# I94100_v1_3 register map
File version: 1.0
Registers are 32-bit, read-write, reset 0x0 unless marked. A register's access mark holds for its fields unless they carry their own. Offsets are from the block's base; [hi:lo] are bit positions; {n}, {i} and the like mark numbered series; 'fields as' and 'values as' point back to an identical list.

## GPIO — GPIO Register Map
Base 0x40004000
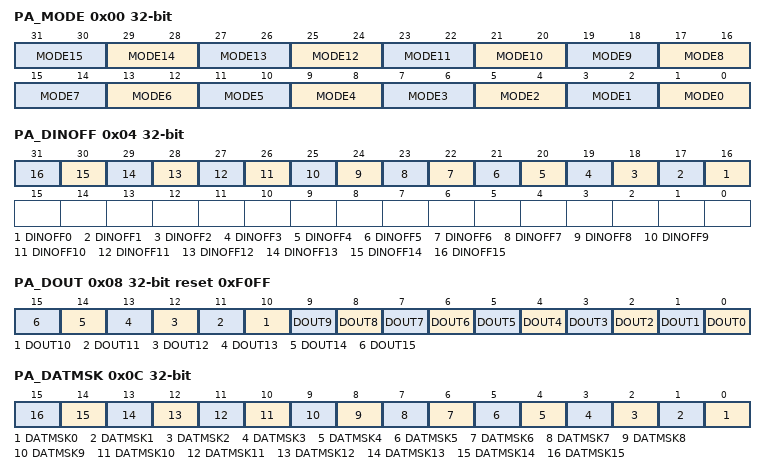
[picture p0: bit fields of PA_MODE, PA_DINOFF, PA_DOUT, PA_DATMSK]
0x00 PA_MODE reset not defined — PA I/O Mode Control
  [all] fields
    0=Px.n is in Input mode; 1=Px.n is in Push-pull Output mode; 2=Px.n is in Open-drain Output mode; 3=Px.n is in Quasi-bidirectional mode
  [2n+1:2n] MODE{n} (n=0..15) — Port A-D I/O Pin[n] Mode Control. Determine each I/O mode of Px.n pins.
0x04 PA_DINOFF — PA Digital Input Path Disable Control
  [all] fields
    0=Px.n digital input path Enabled; 1=Px.n digital input path Disabled (digital input tied to low)
  [n+16] DINOFF{n} (n=0..15) — Port A-D Pin[n] Digital Input Path Disable Control. Each of these bits is used to control if the digital input path of corresponding Px.n pin is disabled. If input is analog signal, users can disable Px.n digital input path to avoid input current leakage.
0x08 PA_DOUT reset 0xF0FF (reset mask 0xFFFFF0FF) — PA Data Output Value
  [all] fields
    0=Px.n will drive Low if the Px.n pin is configured as Push-pull output, Open-drain output or Quasi-bidirectional mode; 1=Px.n will drive High if the Px.n pin is configured as Push-pull output or Quasi-bidirectional mode
  [n] DOUT{n} (n=0..15) — Port A-D Pin[n] Output Value. Each of these bits controls the status of a Px.n pin when the Px.n is configured as Push-pull output, Open-drain output or Quasi-bidirectional mode.
0x0C PA_DATMSK — PA Data Output Write Mask
  [all] fields
    0=Corresponding DOUT (Px_DOUT[n]) bit can be updated; 1=Corresponding DOUT (Px_DOUT[n]) bit protected
  [n] DATMSK{n} (n=0..15) — Port A-D Pin[n] Data Output Write Mask. These bits are used to protect the corresponding DOUT (Px_DOUT[n]) bit. When the DATMSK (Px_DATMSK[n]) bit is set to 1, the corresponding DOUT (Px_DOUT[n]) bit is protected. If the write signal is masked, writing data to the protect bit is ignored.
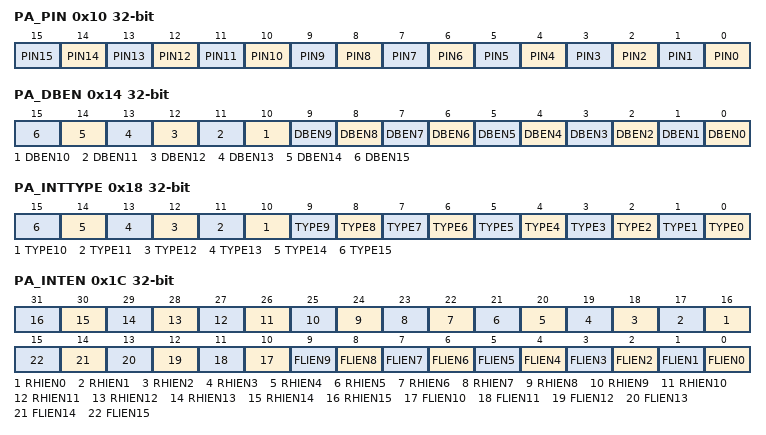
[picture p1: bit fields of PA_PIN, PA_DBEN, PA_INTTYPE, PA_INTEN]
0x10 PA_PIN ro (reset mask 0xFFFF0000) — PA Pin Value
  [n] PIN{n} (n=0..15) — Port A-D Pin[n] Pin Value. Each bit of the register reflects the actual status of the respective Px.n pin. If the bit is 1, it indicates the corresponding pin status is high; else the pin status is low. Note 1: The reset value of PB_PIN[15:8] is XXXX_00XXb in binary form. Note 2:
0x14 PA_DBEN — PA De-bounce Enable Control Register
  [all] fields
    0=Px.n de-bounce function Disabled; 1=Px.n de-bounce function Enabled
  [n] DBEN{n} (n=0..15) — Port A-D Pin[n] Input Signal De-bounce Enable Bit. The DBEN[n] bit is used to enable the de-bounce function for each corresponding bit. If the input signal pulse width cannot be sampled by continuous two de-bounce sample cycle, the input signal transition is seen as the signal bounce and will not trigger the interrupt. The de-bounce clock source is controlled by DBCLKSRC (GPIO_DBCTL [4]), one de-bounce sample cycle period is controlled by DBCLKSEL (GPIO_DBCTL [3:0]).
0x18 PA_INTTYPE — PA Interrupt Trigger Type Control
  [all] fields
    0=Edge trigger interrupt; 1=Level trigger interrupt
  [n] TYPE{n} (n=0..15) — Port A-D Pin[n] Edge or Level Detection Interrupt Trigger Type Control. TYPE (Px_INTTYPE[n]) bit is used to control the triggered interrupt is by level trigger or by edge trigger. If the interrupt is by edge trigger, the trigger source can be controlled by de-bounce. If the interrupt is by level trigger, the input source is sampled by one HCLK clock and generates the interrupt.
0x1C PA_INTEN — PA Interrupt Enable Control Register
  [n+16] RHIEN{n} (n=0..15) — Port A-D Pin[n] Rising Edge or High Level Interrupt Trigger Type Enable Bit. The RHIEN (Px_INTEN[n+16]) bit is used to enable the interrupt for each of the corresponding input Px.n pin. Set bit to 1 also enable the pin wake-up function. When setting the RHIEN (Px_INTEN[n+16]) bit to 1 : If the interrupt is level trigger (TYPE (Px_INTTYPE[n]) bit is set to 1), the input Px.n pin will generate the interrupt while this pin state is at high level. If the interrupt is edge trigger (TYPE (Px_INTTYPE[n]) bit is set to 0), the input Px.n pin will generate the interrupt while this pin state changed from low to high.
    0=Px.n level high or low to high interrupt Disabled; 1=Px.n level high or low to high interrupt Enabled
  [n] FLIEN{n} (n=0..15) — Port A-D Pin[n] Falling Edge or Low Level Interrupt Trigger Type Enable Bit. The FLIEN (Px_INTEN[n]) bit is used to enable the interrupt for each of the corresponding input Px.n pin. Set bit to 1 also enable the pin wake-up function. When setting the FLIEN (Px_INTEN[n]) bit to 1 : If the interrupt is level trigger (TYPE (Px_INTTYPE[n]) bit is set to 1), the input Px.n pin will generate the interrupt while this pin state is at low level. If the interrupt is edge trigger(TYPE (Px_INTTYPE[n]) bit is set to 0), the input Px.n pin will generate the interrupt while this pin state changed from high to low.
    0=Px.n level low or high to low interrupt Disabled; 1=Px.n level low or high to low interrupt Enabled
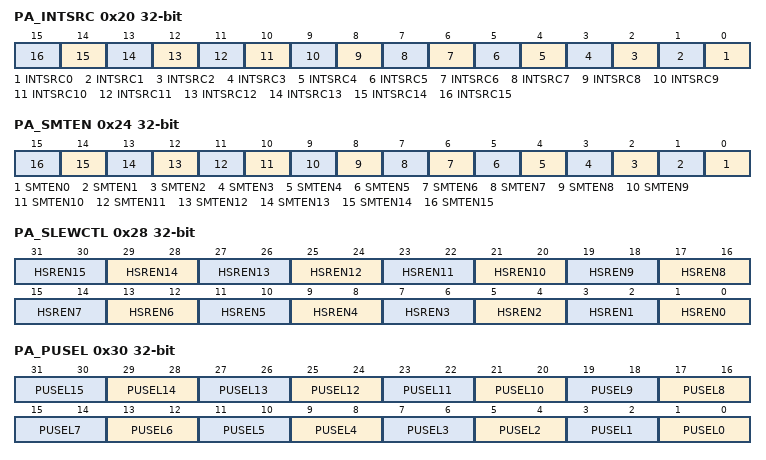
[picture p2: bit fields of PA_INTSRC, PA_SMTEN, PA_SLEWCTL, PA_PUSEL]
0x20 PA_INTSRC — PA Interrupt Source Flag
  [all] fields
    0=No action. No interrupt at Px.n; 1=Clear the corresponding pending interrupt. Px.n generates an interrupt
  [n] INTSRC{n} (n=0..15) — Port A-D Pin[n] Interrupt Source Flag. Write Operation :
0x24 PA_SMTEN — PA Input Schmitt Trigger Enable Register
  [all] fields
    0=Px.n input schmitt trigger function Disabled; 1=Px.n input schmitt trigger function Enabled
  [n] SMTEN{n} (n=0..15) — Port A-D Pin[n] Input Schmitt Trigger Enable Bit
0x28 PA_SLEWCTL — PA High Slew Rate Control Register
  [all] fields
    0=Px.n output with normal slew rate mode; 1=Px.n output with high slew rate mode; 2=Px.n output with fast slew rate mode; 3=Reserved. Do not use
  [2n+1:2n] HSREN{n} (n=0..15) — Port A-D Pin[n] High Slew Rate Control
0x30 PA_PUSEL — PA Pull-up and Pull-down Selection Register
  [all] fields
    0=Px.n pull-up and pull- down disable; 1=Px.n pull-up enable; 2=Px.n pull-down enable; 3=Px.n pull-up and pull-down disable
  [2n+1:2n] PUSEL{n} (n=0..15) — Port A-D Pin[n] Pull-up and Pull-down Enable Register. Determine each I/O Pull-up/pull-down of Px.n pins.
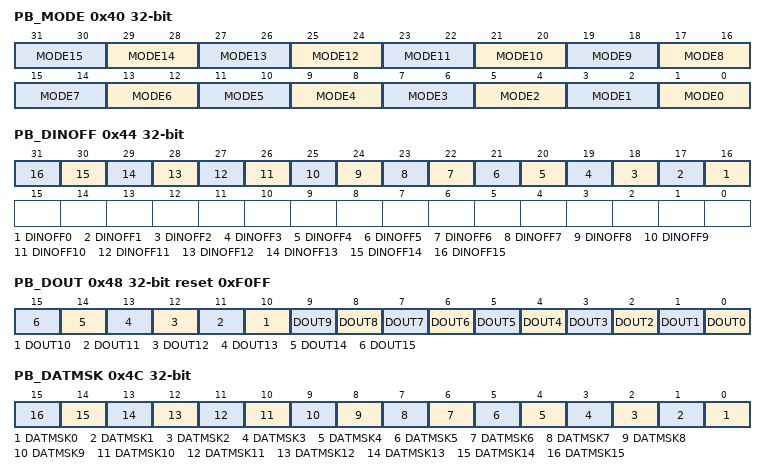
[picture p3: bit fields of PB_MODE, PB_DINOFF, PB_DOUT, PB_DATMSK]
0x40 PB_MODE reset not defined — PB I/O Mode Control
  fields as PA_MODE
0x44 PB_DINOFF — PB Digital Input Path Disable Control
  fields as PA_DINOFF
0x48 PB_DOUT reset 0xF0FF (reset mask 0xFFFFF0FF) — PB Data Output Value
  fields as PA_DOUT
0x4C PB_DATMSK — PB Data Output Write Mask
  fields as PA_DATMSK
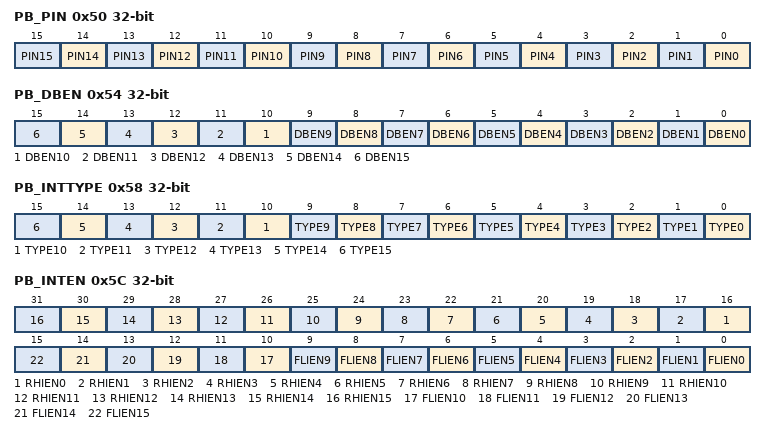
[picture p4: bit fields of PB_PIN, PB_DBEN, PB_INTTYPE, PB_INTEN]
0x50 PB_PIN ro (reset mask 0xFFFF0000) — PB Pin Value
  fields as PA_PIN
0x54 PB_DBEN — PB De-bounce Enable Control Register
  fields as PA_DBEN
0x58 PB_INTTYPE — PB Interrupt Trigger Type Control
  fields as PA_INTTYPE
0x5C PB_INTEN — PB Interrupt Enable Control Register
  fields as PA_INTEN
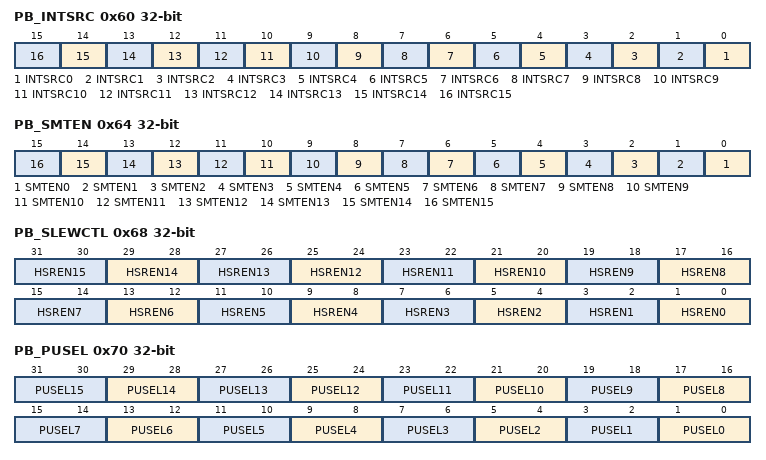
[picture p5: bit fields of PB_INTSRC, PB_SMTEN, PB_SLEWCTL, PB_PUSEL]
0x60 PB_INTSRC — PB Interrupt Source Flag
  fields as PA_INTSRC
0x64 PB_SMTEN — PB Input Schmitt Trigger Enable Register
  fields as PA_SMTEN
0x68 PB_SLEWCTL — PB High Slew Rate Control Register
  fields as PA_SLEWCTL
0x70 PB_PUSEL — PB Pull-up and Pull-down Selection Register
  fields as PA_PUSEL
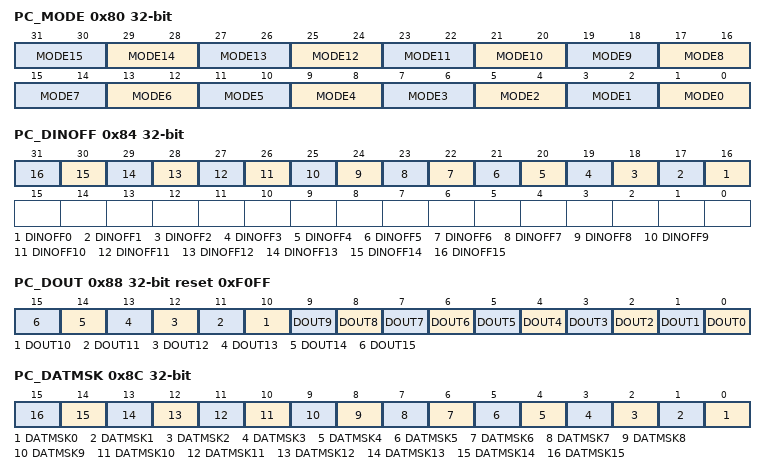
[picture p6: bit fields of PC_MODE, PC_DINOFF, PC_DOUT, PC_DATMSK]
0x80 PC_MODE reset not defined — PC I/O Mode Control
  fields as PA_MODE
0x84 PC_DINOFF — PC Digital Input Path Disable Control
  fields as PA_DINOFF
0x88 PC_DOUT reset 0xF0FF (reset mask 0xFFFFF0FF) — PC Data Output Value
  fields as PA_DOUT
0x8C PC_DATMSK — PC Data Output Write Mask
  fields as PA_DATMSK
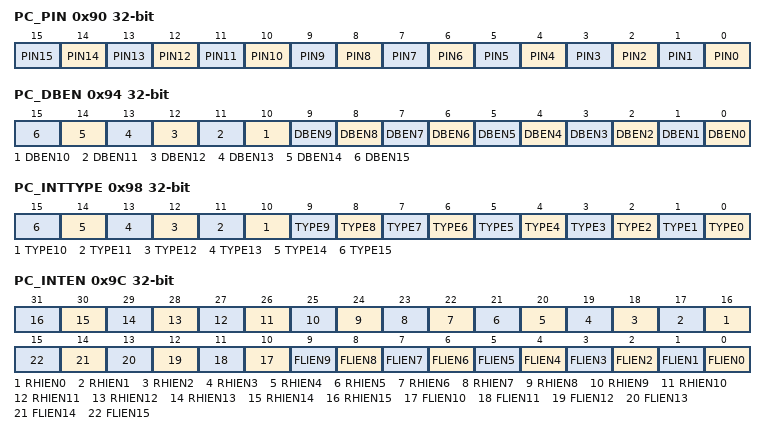
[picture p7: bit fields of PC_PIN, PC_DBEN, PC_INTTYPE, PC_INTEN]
0x90 PC_PIN ro (reset mask 0xFFFF0000) — PC Pin Value
  fields as PA_PIN
0x94 PC_DBEN — PC De-bounce Enable Control Register
  fields as PA_DBEN
0x98 PC_INTTYPE — PC Interrupt Trigger Type Control
  fields as PA_INTTYPE
0x9C PC_INTEN — PC Interrupt Enable Control Register
  fields as PA_INTEN
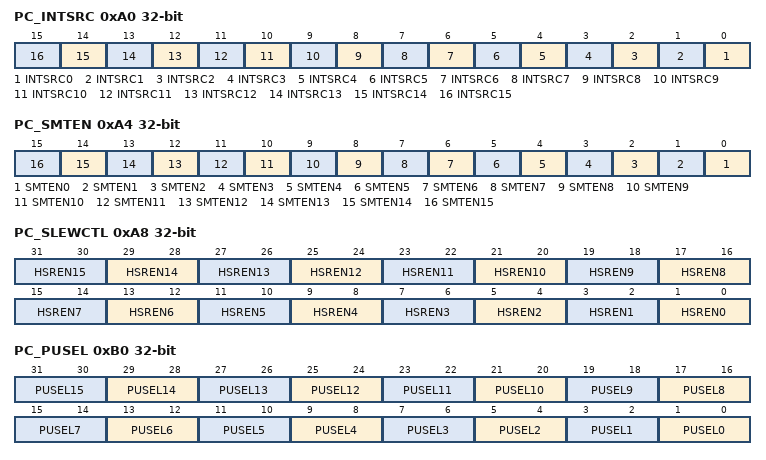
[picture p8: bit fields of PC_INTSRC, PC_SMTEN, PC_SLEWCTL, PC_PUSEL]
0xA0 PC_INTSRC — PC Interrupt Source Flag
  fields as PA_INTSRC
0xA4 PC_SMTEN — PC Input Schmitt Trigger Enable Register
  fields as PA_SMTEN
0xA8 PC_SLEWCTL — PC High Slew Rate Control Register
  fields as PA_SLEWCTL
0xB0 PC_PUSEL — PC Pull-up and Pull-down Selection Register
  fields as PA_PUSEL
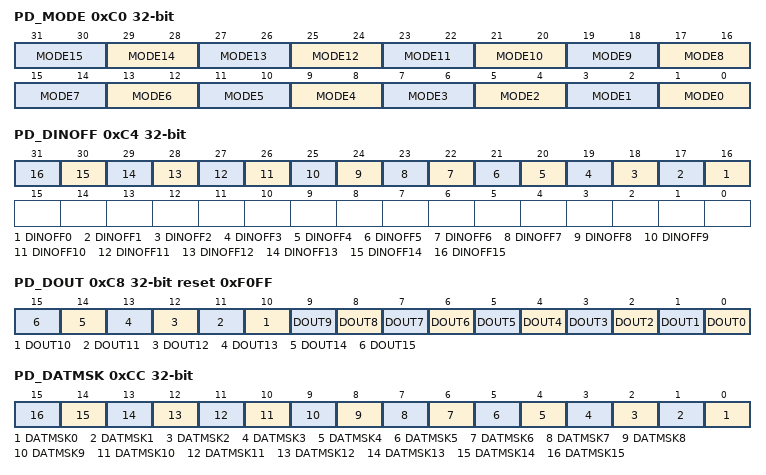
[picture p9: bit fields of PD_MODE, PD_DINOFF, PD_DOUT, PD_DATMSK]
0xC0 PD_MODE reset not defined — PD I/O Mode Control
  fields as PA_MODE
0xC4 PD_DINOFF — PD Digital Input Path Disable Control
  fields as PA_DINOFF
0xC8 PD_DOUT reset 0xF0FF (reset mask 0xFFFFF0FF) — PD Data Output Value
  fields as PA_DOUT
0xCC PD_DATMSK — PD Data Output Write Mask
  fields as PA_DATMSK
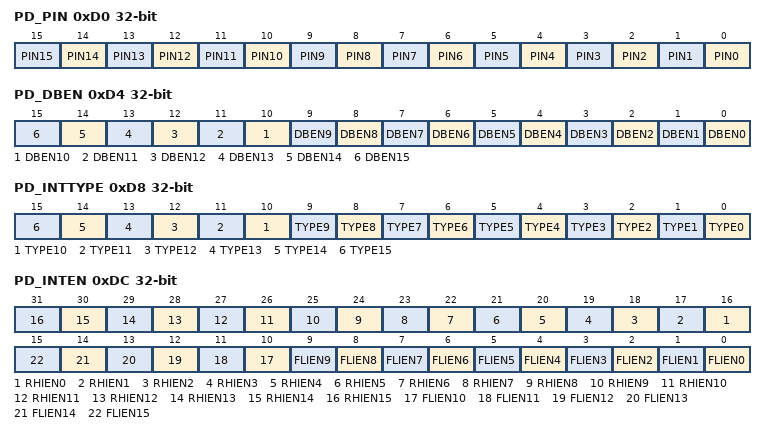
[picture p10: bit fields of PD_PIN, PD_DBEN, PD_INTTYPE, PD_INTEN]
0xD0 PD_PIN ro (reset mask 0xFFFF0000) — PD Pin Value
  fields as PA_PIN
0xD4 PD_DBEN — PD De-bounce Enable Control Register
  fields as PA_DBEN
0xD8 PD_INTTYPE — PD Interrupt Trigger Type Control
  fields as PA_INTTYPE
0xDC PD_INTEN — PD Interrupt Enable Control Register
  fields as PA_INTEN
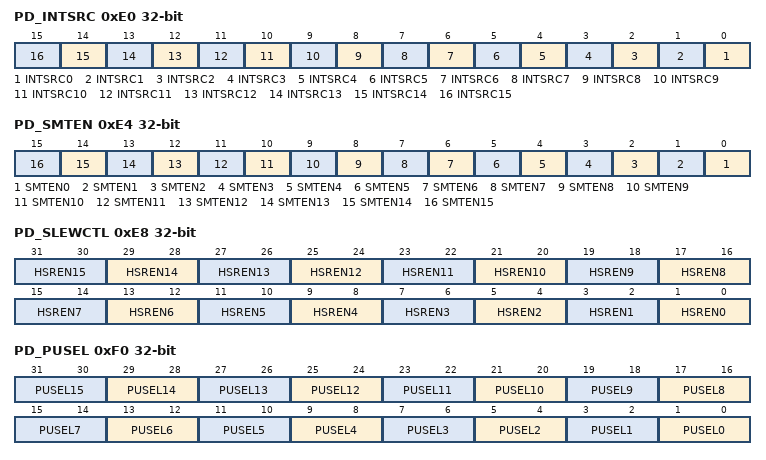
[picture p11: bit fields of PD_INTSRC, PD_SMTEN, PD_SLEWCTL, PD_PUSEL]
0xE0 PD_INTSRC — PD Interrupt Source Flag
  fields as PA_INTSRC
0xE4 PD_SMTEN — PD Input Schmitt Trigger Enable Register
  fields as PA_SMTEN
0xE8 PD_SLEWCTL — PD High Slew Rate Control Register
  fields as PA_SLEWCTL
0xF0 PD_PUSEL — PD Pull-up and Pull-down Selection Register
  fields as PA_PUSEL
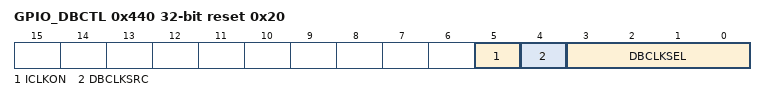
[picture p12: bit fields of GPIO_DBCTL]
0x440 GPIO_DBCTL reset 0x20 — Interrupt De-bounce Control Register
  [5] ICLKON — Interrupt Clock on Mode. Note: It is recommended to disable this bit to save system power if no special application concern.
    0=Edge detection circuit is active only if I/O pin corresponding RHIEN (Px_INTEN[n+16])/FLIEN (Px_INTEN[n]) bit is set to 1; 1=All I/O pins edge detection circuit is always active after reset
  [4] DBCLKSRC — De-bounce Counter Clock Source Selection
    0=De-bounce counter clock source is the HCLK; 1=De-bounce counter clock source is the 10 kHz internal low speed RC oscillator (LIRC)
  [3:0] DBCLKSEL — De-bounce Sampling Cycle Selection
    0=Sample interrupt input once per 1 clocks; 1=Sample interrupt input once per 2 clocks; 2=Sample interrupt input once per 4 clocks; 3=Sample interrupt input once per 8 clocks; 4=Sample interrupt input once per 16 clocks; 5=Sample interrupt input once per 32 clocks; 6=Sample interrupt input once per 64 clocks; 7=Sample interrupt input once per 128 clocks; 8=Sample interrupt input once per 256 clocks; 9=Sample interrupt input once per 2*256 clocks; 10=Sample interrupt input once per 4*256 clocks; 11=Sample interrupt input once per 8*256 clocks; 12=Sample interrupt input once per 16*256 clocks; 13=Sample interrupt input once per 32*256 clocks; 14=Sample interrupt input once per 64*256 clocks; 15=Sample interrupt input once per 128*256 clocks
{0x800+4i} PA{i}_PDIO (reset mask 0xFFFFFFF0) (i=0..15) — GPIO PA.n Pin Data Input/Output Register
  [0] PDIO — GPIO Px.N Pin Data Input/Output. Writing this bit can control one GPIO pin output value.
    0=Corresponding GPIO pin set to low; 1=Corresponding GPIO pin set to high
0x840 PBn_PDIO (reset mask 0xFFFFFFF0) — GPIO PB.n Pin Data Input/Output Register
  fields as PA0_PDIO
{0x880+4i} PC{i}_PDIO (reset mask 0xFFFFFFF0) (i=0..15) — GPIO PC.n Pin Data Input/Output Register
  fields as PA0_PDIO
{0x8C0+4i} PD{i}_PDIO (reset mask 0xFFFFFFF0) (i=0..15) — GPIO PD.n Pin Data Input/Output Register
  fields as PA0_PDIO
